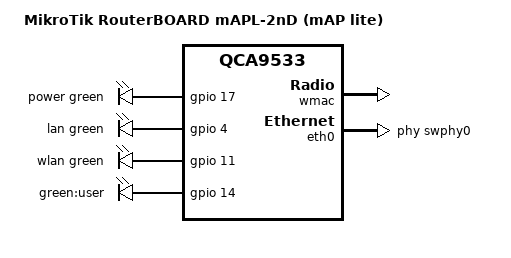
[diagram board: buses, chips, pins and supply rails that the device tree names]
// SPDX-License-Identifier: GPL-2.0-or-later OR MIT

#include <dt-bindings/leds/common.h>

#include "qca9533_mikrotik_routerboard-16m.dtsi"

/ {
	compatible = "mikrotik,routerboard-mapl-2nd", "qca,qca9533";
	model = "MikroTik RouterBOARD mAPL-2nD (mAP lite)";

	aliases {
		led-boot = &led_user;
		led-failsafe = &led_user;
		led-running = &led_user;
		led-upgrade = &led_user;
	};

	leds {
		compatible = "gpio-leds";
		pinctrl-names = "default";
		pinctrl-0 = <&led_power_pin &led_lan_pin>;

		power {
			function = LED_FUNCTION_POWER;
			color = <LED_COLOR_ID_GREEN>;
			gpios = <&gpio 17 GPIO_ACTIVE_HIGH>;
			default-state = "on";
		};

		lan {
			function = LED_FUNCTION_LAN;
			color = <LED_COLOR_ID_GREEN>;
			gpios = <&gpio 4 GPIO_ACTIVE_HIGH>;
		};

		wlan {
			function = LED_FUNCTION_WLAN;
			color = <LED_COLOR_ID_GREEN>;
			gpios = <&gpio 11 GPIO_ACTIVE_HIGH>;
			linux,default-trigger = "phy0tpt";
		};

		led_user: user {
			label = "green:user";
			gpios = <&gpio 14 GPIO_ACTIVE_HIGH>;
		};
	};
};

&wmac {
	status = "okay";

	qca,no-eeprom;
};

&eth0 {
	status = "okay";

	phy-handle = <&swphy0>;

	gmac-config {
		device = <&gmac>;
		switch-phy-swap = <1>;
	};
};

&eth1 {
	compatible = "syscon", "simple-mfd";
};

&pinmux {
	led_lan_pin: pinmux_led_lan_pin {
		pinctrl-single,bits = <0x4 0x0 0xff>;
	};

	led_power_pin: pinmux_led_power_pin {
		pinctrl-single,bits = <0x10 0x0 0xff00>;
	};
};
